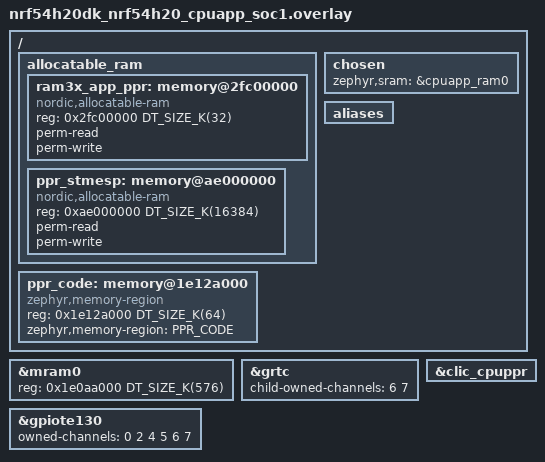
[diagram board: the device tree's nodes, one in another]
/*
 * Copyright (c) 2023 Nordic Semiconductor ASA
 *
 * SPDX-License-Identifier: Apache-2.0
 */

 #include "../app.overlay"

 /delete-node/ &led1;
 /delete-node/ &button1;

 /{
	allocatable_ram {
		#address-cells = <1>;
		#size-cells = <1>;

		/* Configure PPR memory region. Allow to use defined RAM
		 * region by App and cores owned by App.
		 */
		ram3x_app_ppr: memory@2fc00000 {
			compatible = "nordic,allocatable-ram";
			reg = <0x2fc00000 DT_SIZE_K(32)>;
			perm-read;
			perm-write;
		};

		ppr_stmesp: memory@ae000000 {
			compatible = "nordic,allocatable-ram";
			reg = <0xae000000 DT_SIZE_K(16384)>;
			perm-read;
			perm-write;
		};
	};

	chosen {
		zephyr,sram = &cpuapp_ram0;
	};

	aliases {
		/delete-property/ sw1;
		/delete-property/ led1;
	};

	/* Configure PPR code region. Allow to execute from defined
	 * region by App and cores owned by App.
	 */
	ppr_code: memory@1e12a000 {
		compatible = "zephyr,memory-region", "mmio-sram";
		reg = <0x1e12a000 DT_SIZE_K(64)>;
		zephyr,memory-region = "PPR_CODE";
	};
};

&mram0 {
	/* Expand to include PPR */
	reg = <0x1e0aa000 DT_SIZE_K(576)>;
};

&grtc {
	status = "okay";
	/* Channels 6 and 7 are owned by App but used by PPR. */
	child-owned-channels = <6 7>;
};

/* Enable PPR clic so App could start PPR. */
&clic_cpuppr {
	status = "okay";
};

&gpiote130 {
	owned-channels = <0 2 4 5 6 7>;
	status = "okay";
};
